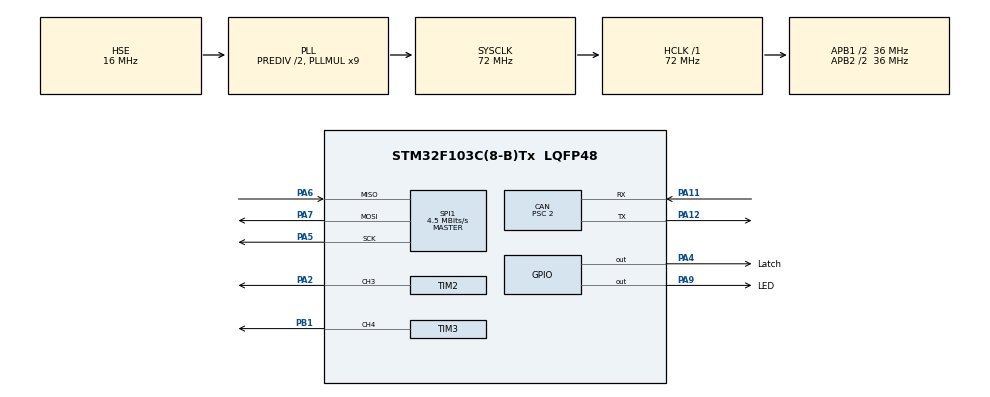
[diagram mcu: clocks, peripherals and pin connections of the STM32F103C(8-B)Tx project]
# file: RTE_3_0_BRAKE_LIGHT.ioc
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CAN.ABOM=ENABLE
CAN.BS1=CAN_BS1_9TQ
CAN.BS2=CAN_BS2_8TQ
CAN.CalculateBaudRate=1000000
CAN.CalculateTimeBit=1000
CAN.CalculateTimeQuantum=55.55555555555556
CAN.Prescaler=2
Dma.Request0=SPI1_TX
Dma.Request1=SPI1_RX
Dma.SPI1_RX.1.Direction=DMA_PERIPH_TO_MEMORY
Dma.SPI1_RX.1.Instance=DMA1_Channel2
Dma.SPI1_RX.1.MemDataAlignment=DMA_MDATAALIGN_BYTE
Dma.SPI1_RX.1.MemInc=DMA_MINC_ENABLE
Dma.SPI1_RX.1.Mode=DMA_NORMAL
Dma.SPI1_RX.1.PeriphDataAlignment=DMA_PDATAALIGN_BYTE
Dma.SPI1_RX.1.PeriphInc=DMA_PINC_DISABLE
Dma.SPI1_RX.1.Priority=DMA_PRIORITY_LOW
Dma.SPI1_TX.0.Direction=DMA_MEMORY_TO_PERIPH
Dma.SPI1_TX.0.Instance=DMA1_Channel3
Dma.SPI1_TX.0.MemDataAlignment=DMA_MDATAALIGN_BYTE
Dma.SPI1_TX.0.MemInc=DMA_MINC_ENABLE
Dma.SPI1_TX.0.Mode=DMA_NORMAL
Dma.SPI1_TX.0.PeriphDataAlignment=DMA_PDATAALIGN_BYTE
Dma.SPI1_TX.0.PeriphInc=DMA_PINC_DISABLE
Dma.SPI1_TX.0.Priority=DMA_PRIORITY_LOW
Mcu.Family=STM32F1
Mcu.Name=STM32F103C(8-B)Tx
Mcu.Package=LQFP48
NVIC.CAN1_RX1_IRQn=true\:0\:0\:false\:false\:true\:true\:true\:true
NVIC.CAN1_SCE_IRQn=true\:0\:0\:false\:false\:true\:true\:true\:true
NVIC.DMA1_Channel2_IRQn=true\:0\:0\:false\:false\:true\:false\:true\:true
NVIC.DMA1_Channel3_IRQn=true\:0\:0\:false\:false\:true\:false\:true\:true
NVIC.PriorityGroup=NVIC_PRIORITYGROUP_4
NVIC.USB_HP_CAN1_TX_IRQn=true\:0\:0\:false\:false\:true\:true\:true\:true
NVIC.USB_LP_CAN1_RX0_IRQn=true\:0\:0\:false\:false\:true\:true\:true\:true
PA11.Mode=CAN_Activate
PA11.Signal=CAN_RX
PA12.Mode=CAN_Activate
PA12.Signal=CAN_TX
PA13.Mode=Serial_Wire
PA13.Signal=SYS_JTMS-SWDIO
PA14.Mode=Serial_Wire
PA14.Signal=SYS_JTCK-SWCLK
PA2.Signal=S_TIM2_CH3
PA4.GPIO_Label=Latch
PA4.Signal=GPIO_Output
PA5.Mode=Full_Duplex_Master
PA5.Signal=SPI1_SCK
PA6.Mode=Full_Duplex_Master
PA6.Signal=SPI1_MISO
PA7.Mode=Full_Duplex_Master
PA7.Signal=SPI1_MOSI
PA9.GPIO_Label=LED
PA9.Signal=GPIO_Output
PB1.Signal=S_TIM3_CH4
PD0-OSC_IN.Mode=HSE-External-Clock-Source
PD0-OSC_IN.Signal=RCC_OSC_IN
PD1-OSC_OUT.Mode=HSE-External-Clock-Source
PD1-OSC_OUT.Signal=RCC_OSC_OUT
ProjectManager.HeapSize=0x200
ProjectManager.StackSize=0x400
ProjectManager.TargetToolchain=STM32CubeIDE
RCC.AHBFreq_Value=72000000
RCC.APB1CLKDivider=RCC_HCLK_DIV2
RCC.APB1Freq_Value=36000000
RCC.APB1TimFreq_Value=72000000
RCC.APB2CLKDivider=RCC_HCLK_DIV2
RCC.APB2Freq_Value=36000000
RCC.APB2TimFreq_Value=72000000
RCC.HCLKFreq_Value=72000000
RCC.HSEDivPLL=RCC_HSE_PREDIV_DIV2
RCC.HSE_VALUE=16000000
RCC.PLLMUL=RCC_PLL_MUL9
RCC.PLLSourceVirtual=RCC_PLLSOURCE_HSE
RCC.SYSCLKFreq_VALUE=72000000
RCC.SYSCLKSource=RCC_SYSCLKSOURCE_PLLCLK
RCC.USBFreq_Value=72000000
SH.S_TIM2_CH3.0=TIM2_CH3,PWM Generation3 CH3
SH.S_TIM3_CH4.0=TIM3_CH4,PWM Generation4 CH4
SPI1.BaudRatePrescaler=SPI_BAUDRATEPRESCALER_8
SPI1.CalculateBaudRate=4.5 MBits/s
SPI1.DataSize=SPI_DATASIZE_8BIT
SPI1.Direction=SPI_DIRECTION_2LINES
SPI1.FirstBit=SPI_FIRSTBIT_LSB
SPI1.Mode=SPI_MODE_MASTER
SPI1.VirtualType=VM_MASTER
TIM2.Channel-PWM\ Generation3\ CH3=TIM_CHANNEL_3
TIM2.Period=99
TIM2.Prescaler=28
TIM3.Channel-PWM\ Generation4\ CH4=TIM_CHANNEL_4
TIM3.Period=1000
TIM3.Prescaler=35
VP_TIM2_VS_ClockSourceINT.Mode=Internal
VP_TIM3_VS_ClockSourceINT.Mode=Internal
board=custom

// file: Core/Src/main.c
/* USER CODE BEGIN Header */
/**
  ******************************************************************************
  * @file           : main.c
  * @brief          : Main program body
  ******************************************************************************
  * @attention
  *
  * Copyright (c) 2024 STMicroelectronics.
  * All rights reserved.
  *
  * This software is licensed under terms that can be found in the LICENSE file
  * in the root directory of this software component.
  * If no LICENSE file comes with this software, it is provided AS-IS.
  *
  ******************************************************************************
  */
/* USER CODE END Header */
#include "main.h"
#include "can.h"
#include "dma.h"
#include "spi.h"
#include "tim.h"
#include "gpio.h"

/* USER CODE BEGIN Includes */
#include "app.h"
/* USER CODE END Includes */

void SystemClock_Config(void);

int main(void)
{

  /* MCU Configuration--------------------------------------------------------*/

  /* Reset of all peripherals, Initializes the Flash interface and the Systick. */
  HAL_Init();

  /* Configure the system clock */
  SystemClock_Config();

  /* Initialize all configured peripherals */
  MX_GPIO_Init();
  MX_DMA_Init();
  MX_CAN_Init();
  MX_SPI1_Init();
  MX_TIM2_Init();
  MX_TIM3_Init();

  /* Infinite loop */
  /* USER CODE BEGIN WHILE */
  while (1)
  {
	  mainApp();
    /* USER CODE END WHILE */

  }
}

void SystemClock_Config(void)
{
  RCC_OscInitTypeDef RCC_OscInitStruct = {0};
  RCC_ClkInitTypeDef RCC_ClkInitStruct = {0};

  /** Initializes the RCC Oscillators according to the specified parameters
  * in the RCC_OscInitTypeDef structure.
  */
  RCC_OscInitStruct.OscillatorType = RCC_OSCILLATORTYPE_HSE;
  RCC_OscInitStruct.HSEState = RCC_HSE_BYPASS;
  RCC_OscInitStruct.HSEPredivValue = RCC_HSE_PREDIV_DIV2;
  RCC_OscInitStruct.HSIState = RCC_HSI_ON;
  RCC_OscInitStruct.PLL.PLLState = RCC_PLL_ON;
  RCC_OscInitStruct.PLL.PLLSource = RCC_PLLSOURCE_HSE;
  RCC_OscInitStruct.PLL.PLLMUL = RCC_PLL_MUL9;
  if (HAL_RCC_OscConfig(&RCC_OscInitStruct) != HAL_OK)
  {
    Error_Handler();
  }

  /** Initializes the CPU, AHB and APB buses clocks
  */
  RCC_ClkInitStruct.ClockType = RCC_CLOCKTYPE_HCLK|RCC_CLOCKTYPE_SYSCLK
                              |RCC_CLOCKTYPE_PCLK1|RCC_CLOCKTYPE_PCLK2;
  RCC_ClkInitStruct.SYSCLKSource = RCC_SYSCLKSOURCE_PLLCLK;
  RCC_ClkInitStruct.AHBCLKDivider = RCC_SYSCLK_DIV1;
  RCC_ClkInitStruct.APB1CLKDivider = RCC_HCLK_DIV2;
  RCC_ClkInitStruct.APB2CLKDivider = RCC_HCLK_DIV2;

  if (HAL_RCC_ClockConfig(&RCC_ClkInitStruct, FLASH_LATENCY_2) != HAL_OK)
  {
    Error_Handler();
  }
}

void Error_Handler(void)
{
  __disable_irq();
  while (1)
  {
  }
}
